AUTOSAR XML (schema 4-3-0)
package /MICROSAR/FiM_swc/DataTypes
  impl type FiM_FunctionIdType: range raw 0..255, implementation-data-type=uint8
package /MICROSAR/FiM_swc/Interfaces
  client server interface FunctionInhibition: is-service=true, service-kind=FUNCTION-INHIBITION-MANAGER
    operation GetFunctionPermission: possible-error=E_NOT_OK
      arg Permission: type=boolean, direction=OUT
    error E_NOT_OK: error-code=1
package /MICROSAR/FiM_swc/ComponentTypes
  service sw component type FiMMaster_INVALID_OSAPPLICATION: category=SERVICE_COMPONENT
    behavior FiMMaster_INVALID_OSAPPLICATIONInternalBehavior: handle-termination-and-restart=NO-SUPPORT
      timing event Timer_FiMMaster_INVALID_OSAPPLICATION_MainFunction: start-on-event=FiMMaster_INVALID_OSAPPLICATION_MainFunction, period=0.01
      runnable FiMMaster_INVALID_OSAPPLICATION_MainFunction: symbol=FiM_MainFunction
  swc implementation FiMMaster_INVALID_OSAPPLICATIONImplementation: programming-language=C, behavior=FiMMaster_INVALID_OSAPPLICATIONInternalBehavior
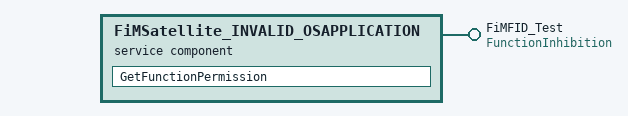
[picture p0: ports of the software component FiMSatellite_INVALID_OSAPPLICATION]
  service sw component type FiMSatellite_INVALID_OSAPPLICATION: category=SERVICE_COMPONENT
    provide port FiMFID_Test: provided-interface=FunctionInhibition
    behavior FiMSatellite_INVALID_OSAPPLICATIONInternalBehavior: handle-termination-and-restart=NO-SUPPORT, included-data-type-set=data-type=FiM_FunctionIdType, port-api-option{enable-take-address=true, indirect-api=false, port-defined-argument-value{value=0, value-type=FiM_FunctionIdType}, port=FiMFID_Test}
      operation invoked event OpEventGetFunctionPermission_GetFunctionPermission_FiMFID_Test: start-on-event=GetFunctionPermission, operation=FiMFID_Test.GetFunctionPermission
      runnable GetFunctionPermission: can-be-invoked-concurrently=true, symbol=FiM_GetFunctionPermission
  swc implementation FiMSatellite_INVALID_OSAPPLICATIONImplementation: programming-language=C, behavior=FiMSatellite_INVALID_OSAPPLICATIONInternalBehavior
